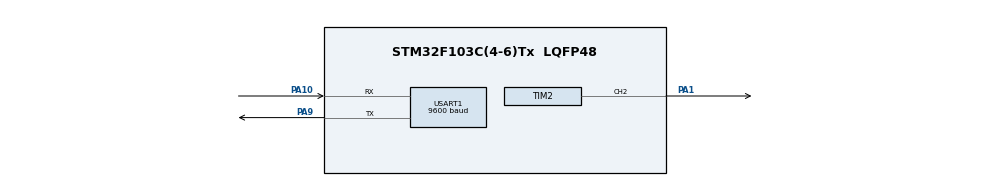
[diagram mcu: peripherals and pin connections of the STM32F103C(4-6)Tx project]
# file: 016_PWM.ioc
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Mcu.Family=STM32F1
Mcu.Name=STM32F103C(4-6)Tx
Mcu.Package=LQFP48
NVIC.PriorityGroup=NVIC_PRIORITYGROUP_4
PA1.Signal=S_TIM2_CH2
PA10.Mode=Asynchronous
PA10.Signal=USART1_RX
PA9.Mode=Asynchronous
PA9.Signal=USART1_TX
PD0-OSC_IN.Mode=HSE-External-Oscillator
PD0-OSC_IN.Signal=RCC_OSC_IN
PD1-OSC_OUT.Mode=HSE-External-Oscillator
PD1-OSC_OUT.Signal=RCC_OSC_OUT
ProjectManager.HeapSize=0x200
ProjectManager.StackSize=0x400
ProjectManager.TargetToolchain=STM32CubeIDE
RCC.APB1Freq_Value=8000000
RCC.APB2Freq_Value=8000000
SH.S_TIM2_CH2.0=TIM2_CH2,PWM Generation2 CH2
TIM2.Channel-PWM\ Generation2\ CH2=TIM_CHANNEL_2
TIM2.Period=99
TIM2.Prescaler=799
USART1.BaudRate=9600
USART1.VirtualMode=VM_ASYNC
VP_SYS_VS_ND.Mode=No_Debug
VP_TIM2_VS_ClockSourceINT.Mode=Internal
board=custom

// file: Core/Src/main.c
/* USER CODE BEGIN Header */
/**
  ******************************************************************************
  * @file           : main.c
  * @brief          : Main program body
  ******************************************************************************
  * @attention
  *
  * <h2><center>&copy; Copyright (c) 2021 STMicroelectronics.
  * All rights reserved.</center></h2>
  *
  * This software component is licensed by ST under BSD 3-Clause license,
  * the "License"; You may not use this file except in compliance with the
  * License. You may obtain a copy of the License at:
  *                        opensource.org/licenses/BSD-3-Clause
  *
  ******************************************************************************
  */
/* USER CODE END Header */
#include "main.h"

TIM_HandleTypeDef htim2;

UART_HandleTypeDef huart1;

/* USER CODE BEGIN PV */

uint8_t PWM=0;

/* USER CODE END PV */

void SystemClock_Config(void);
static void MX_GPIO_Init(void);
static void MX_TIM2_Init(void);
static void MX_USART1_UART_Init(void);

int main(void)
{

  /* MCU Configuration--------------------------------------------------------*/

  /* Reset of all peripherals, Initializes the Flash interface and the Systick. */
  HAL_Init();

  /* Configure the system clock */
  SystemClock_Config();

  /* Initialize all configured peripherals */
  MX_GPIO_Init();
  MX_TIM2_Init();
  MX_USART1_UART_Init();
  /* USER CODE BEGIN 2 */

  HAL_TIM_PWM_Start(&htim2, TIM_CHANNEL_2);

  /* USER CODE END 2 */

  /* Infinite loop */
  while (1)
  {
	  if(PWM<=100)
	  {
		  PWM++;
		  __HAL_TIM_SET_COMPARE(&htim2,TIM_CHANNEL_2,PWM);
		  HAL_Delay(50);
	  }
	  if(PWM)
	  {
		  PWM--;
		  __HAL_TIM_SET_COMPARE(&htim2,TIM_CHANNEL_2,PWM);
		  HAL_Delay(50);
	  }

  }
}

void SystemClock_Config(void)
{
  RCC_OscInitTypeDef RCC_OscInitStruct = {0};
  RCC_ClkInitTypeDef RCC_ClkInitStruct = {0};

  /** Initializes the RCC Oscillators according to the specified parameters
  * in the RCC_OscInitTypeDef structure.
  */
  RCC_OscInitStruct.OscillatorType = RCC_OSCILLATORTYPE_HSI;
  RCC_OscInitStruct.HSIState = RCC_HSI_ON;
  RCC_OscInitStruct.HSICalibrationValue = RCC_HSICALIBRATION_DEFAULT;
  RCC_OscInitStruct.PLL.PLLState = RCC_PLL_NONE;
  if (HAL_RCC_OscConfig(&RCC_OscInitStruct) != HAL_OK)
  {
    Error_Handler();
  }
  /** Initializes the CPU, AHB and APB buses clocks
  */
  RCC_ClkInitStruct.ClockType = RCC_CLOCKTYPE_HCLK|RCC_CLOCKTYPE_SYSCLK
                              |RCC_CLOCKTYPE_PCLK1|RCC_CLOCKTYPE_PCLK2;
  RCC_ClkInitStruct.SYSCLKSource = RCC_SYSCLKSOURCE_HSI;
  RCC_ClkInitStruct.AHBCLKDivider = RCC_SYSCLK_DIV1;
  RCC_ClkInitStruct.APB1CLKDivider = RCC_HCLK_DIV1;
  RCC_ClkInitStruct.APB2CLKDivider = RCC_HCLK_DIV1;

  if (HAL_RCC_ClockConfig(&RCC_ClkInitStruct, FLASH_LATENCY_0) != HAL_OK)
  {
    Error_Handler();
  }
}

static void MX_TIM2_Init(void)
{

  TIM_ClockConfigTypeDef sClockSourceConfig = {0};
  TIM_MasterConfigTypeDef sMasterConfig = {0};
  TIM_OC_InitTypeDef sConfigOC = {0};

  htim2.Instance = TIM2;
  htim2.Init.Prescaler = 799;
  htim2.Init.CounterMode = TIM_COUNTERMODE_UP;
  htim2.Init.Period = 99;
  htim2.Init.ClockDivision = TIM_CLOCKDIVISION_DIV1;
  htim2.Init.AutoReloadPreload = TIM_AUTORELOAD_PRELOAD_DISABLE;
  if (HAL_TIM_Base_Init(&htim2) != HAL_OK)
  {
    Error_Handler();
  }
  sClockSourceConfig.ClockSource = TIM_CLOCKSOURCE_INTERNAL;
  if (HAL_TIM_ConfigClockSource(&htim2, &sClockSourceConfig) != HAL_OK)
  {
    Error_Handler();
  }
  if (HAL_TIM_PWM_Init(&htim2) != HAL_OK)
  {
    Error_Handler();
  }
  sMasterConfig.MasterOutputTrigger = TIM_TRGO_RESET;
  sMasterConfig.MasterSlaveMode = TIM_MASTERSLAVEMODE_DISABLE;
  if (HAL_TIMEx_MasterConfigSynchronization(&htim2, &sMasterConfig) != HAL_OK)
  {
    Error_Handler();
  }
  sConfigOC.OCMode = TIM_OCMODE_PWM1;
  sConfigOC.Pulse = 0;
  sConfigOC.OCPolarity = TIM_OCPOLARITY_HIGH;
  sConfigOC.OCFastMode = TIM_OCFAST_DISABLE;
  if (HAL_TIM_PWM_ConfigChannel(&htim2, &sConfigOC, TIM_CHANNEL_2) != HAL_OK)
  {
    Error_Handler();
  }
  HAL_TIM_MspPostInit(&htim2);

}

static void MX_USART1_UART_Init(void)
{

  huart1.Instance = USART1;
  huart1.Init.BaudRate = 9600;
  huart1.Init.WordLength = UART_WORDLENGTH_8B;
  huart1.Init.StopBits = UART_STOPBITS_1;
  huart1.Init.Parity = UART_PARITY_NONE;
  huart1.Init.Mode = UART_MODE_TX_RX;
  huart1.Init.HwFlowCtl = UART_HWCONTROL_NONE;
  huart1.Init.OverSampling = UART_OVERSAMPLING_16;
  if (HAL_UART_Init(&huart1) != HAL_OK)
  {
    Error_Handler();
  }

}

static void MX_GPIO_Init(void)
{

  /* GPIO Ports Clock Enable */
  __HAL_RCC_GPIOD_CLK_ENABLE();
  __HAL_RCC_GPIOA_CLK_ENABLE();

}

void Error_Handler(void)
{
}

/************************ (C) COPYRIGHT STMicroelectronics *****END OF FILE****/
